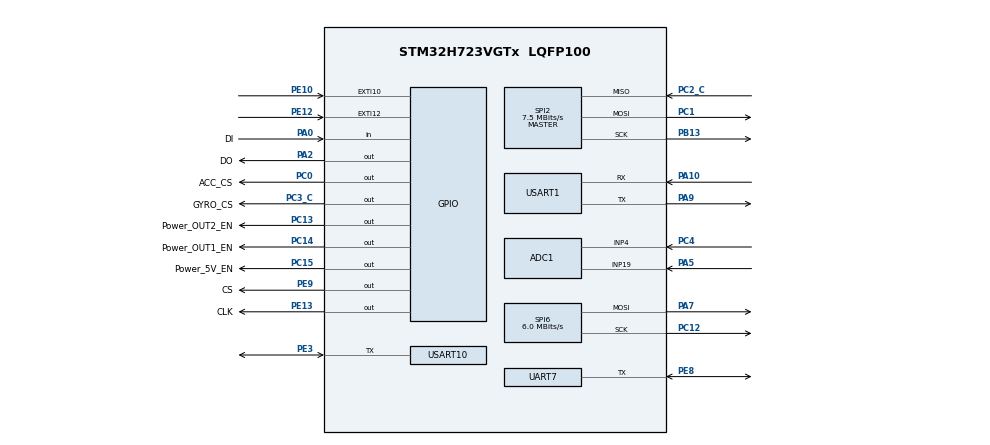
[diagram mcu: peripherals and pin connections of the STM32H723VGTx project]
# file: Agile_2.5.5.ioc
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ADC1.Channel-0\#ChannelRegularConversion=ADC_CHANNEL_4
ADC1.Channel-1\#ChannelRegularConversion=ADC_CHANNEL_19
ADC1.ClockPrescaler=ADC_CLOCK_ASYNC_DIV64
ADC1.ContinuousConvMode=ENABLE
ADC1.ConversionDataManagement=ADC_CONVERSIONDATA_DMA_CIRCULAR
ADC1.NbrOfConversion=2
ADC1.NbrOfConversionFlag=1
ADC1.OffsetNumber-0\#ChannelRegularConversion=ADC_OFFSET_NONE
ADC1.OffsetNumber-1\#ChannelRegularConversion=ADC_OFFSET_NONE
ADC1.OffsetSignedSaturation-0\#ChannelRegularConversion=DISABLE
ADC1.OffsetSignedSaturation-1\#ChannelRegularConversion=DISABLE
ADC1.Rank-0\#ChannelRegularConversion=1
ADC1.Rank-1\#ChannelRegularConversion=2
ADC1.SamplingTime-0\#ChannelRegularConversion=ADC_SAMPLETIME_32CYCLES_5
ADC1.SamplingTime-1\#ChannelRegularConversion=ADC_SAMPLETIME_32CYCLES_5
ADC1.master=1
Bdma.Request0=SPI6_TX
Bdma.RequestsNb=1
Bdma.SPI6_TX.0.Direction=DMA_MEMORY_TO_PERIPH
Bdma.SPI6_TX.0.EventEnable=DISABLE
Bdma.SPI6_TX.0.Instance=BDMA_Channel0
Bdma.SPI6_TX.0.MemDataAlignment=DMA_MDATAALIGN_BYTE
Bdma.SPI6_TX.0.MemInc=DMA_MINC_ENABLE
Bdma.SPI6_TX.0.Mode=DMA_NORMAL
Bdma.SPI6_TX.0.PeriphDataAlignment=DMA_PDATAALIGN_BYTE
Bdma.SPI6_TX.0.PeriphInc=DMA_PINC_DISABLE
Bdma.SPI6_TX.0.Polarity=HAL_DMAMUX_REQ_GEN_RISING
Bdma.SPI6_TX.0.Priority=DMA_PRIORITY_LOW
Bdma.SPI6_TX.0.RequestNumber=1
Bdma.SPI6_TX.0.SignalID=NONE
Bdma.SPI6_TX.0.SyncEnable=DISABLE
Bdma.SPI6_TX.0.SyncPolarity=HAL_DMAMUX_SYNC_NO_EVENT
Bdma.SPI6_TX.0.SyncRequestNumber=1
Bdma.SPI6_TX.0.SyncSignalID=NONE
CORTEX_M7.CPU_ICache=Enabled
CORTEX_M7.MPU_Control=__NULL
CORTEX_M7.default_mode_Activation=1
Dma.ADC1.0.Direction=DMA_PERIPH_TO_MEMORY
Dma.ADC1.0.EventEnable=DISABLE
Dma.ADC1.0.FIFOMode=DMA_FIFOMODE_DISABLE
Dma.ADC1.0.Instance=DMA1_Stream0
Dma.ADC1.0.MemDataAlignment=DMA_MDATAALIGN_HALFWORD
Dma.ADC1.0.MemInc=DMA_MINC_ENABLE
Dma.ADC1.0.Mode=DMA_CIRCULAR
Dma.ADC1.0.PeriphDataAlignment=DMA_PDATAALIGN_HALFWORD
Dma.ADC1.0.PeriphInc=DMA_PINC_DISABLE
Dma.ADC1.0.Polarity=HAL_DMAMUX_REQ_GEN_RISING
Dma.ADC1.0.Priority=DMA_PRIORITY_LOW
Dma.ADC1.0.RequestNumber=1
Dma.ADC1.0.SignalID=NONE
Dma.ADC1.0.SyncEnable=DISABLE
Dma.ADC1.0.SyncPolarity=HAL_DMAMUX_SYNC_NO_EVENT
Dma.ADC1.0.SyncRequestNumber=1
Dma.ADC1.0.SyncSignalID=NONE
Dma.Request0=ADC1
Dma.Request1=USART1_RX
Dma.Request2=USART1_TX
Dma.Request3=UART7_RX
Dma.Request4=UART7_TX
Dma.Request5=USART10_RX
Dma.Request6=USART10_TX
Dma.Request7=SPI2_TX
Dma.Request8=SPI2_RX
Dma.SPI2_RX.8.Direction=DMA_PERIPH_TO_MEMORY
Dma.SPI2_RX.8.EventEnable=DISABLE
Dma.SPI2_RX.8.FIFOMode=DMA_FIFOMODE_DISABLE
Dma.SPI2_RX.8.Instance=DMA2_Stream0
Dma.SPI2_RX.8.MemDataAlignment=DMA_MDATAALIGN_BYTE
Dma.SPI2_RX.8.MemInc=DMA_MINC_ENABLE
Dma.SPI2_RX.8.Mode=DMA_NORMAL
Dma.SPI2_RX.8.PeriphDataAlignment=DMA_PDATAALIGN_BYTE
Dma.SPI2_RX.8.PeriphInc=DMA_PINC_DISABLE
Dma.SPI2_RX.8.Polarity=HAL_DMAMUX_REQ_GEN_RISING
Dma.SPI2_RX.8.Priority=DMA_PRIORITY_LOW
Dma.SPI2_RX.8.RequestNumber=1
Dma.SPI2_RX.8.SignalID=NONE
Dma.SPI2_RX.8.SyncEnable=DISABLE
Dma.SPI2_RX.8.SyncPolarity=HAL_DMAMUX_SYNC_NO_EVENT
Dma.SPI2_RX.8.SyncRequestNumber=1
Dma.SPI2_RX.8.SyncSignalID=NONE
Dma.SPI2_TX.7.Direction=DMA_MEMORY_TO_PERIPH
Dma.SPI2_TX.7.EventEnable=DISABLE
Dma.SPI2_TX.7.FIFOMode=DMA_FIFOMODE_DISABLE
Dma.SPI2_TX.7.Instance=DMA1_Stream7
Dma.SPI2_TX.7.MemDataAlignment=DMA_MDATAALIGN_BYTE
Dma.SPI2_TX.7.MemInc=DMA_MINC_ENABLE
Dma.SPI2_TX.7.Mode=DMA_NORMAL
Dma.SPI2_TX.7.PeriphDataAlignment=DMA_PDATAALIGN_BYTE
Dma.SPI2_TX.7.PeriphInc=DMA_PINC_DISABLE
Dma.SPI2_TX.7.Polarity=HAL_DMAMUX_REQ_GEN_RISING
Dma.SPI2_TX.7.Priority=DMA_PRIORITY_LOW
Dma.SPI2_TX.7.RequestNumber=1
Dma.SPI2_TX.7.SignalID=NONE
Dma.SPI2_TX.7.SyncEnable=DISABLE
Dma.SPI2_TX.7.SyncPolarity=HAL_DMAMUX_SYNC_NO_EVENT
Dma.SPI2_TX.7.SyncRequestNumber=1
Dma.SPI2_TX.7.SyncSignalID=NONE
Dma.UART7_RX.3.Direction=DMA_PERIPH_TO_MEMORY
Dma.UART7_RX.3.EventEnable=DISABLE
Dma.UART7_RX.3.FIFOMode=DMA_FIFOMODE_DISABLE
Dma.UART7_RX.3.Instance=DMA1_Stream3
Dma.UART7_RX.3.MemDataAlignment=DMA_MDATAALIGN_BYTE
Dma.UART7_RX.3.MemInc=DMA_MINC_ENABLE
Dma.UART7_RX.3.Mode=DMA_NORMAL
Dma.UART7_RX.3.PeriphDataAlignment=DMA_PDATAALIGN_BYTE
Dma.UART7_RX.3.PeriphInc=DMA_PINC_DISABLE
Dma.UART7_RX.3.Polarity=HAL_DMAMUX_REQ_GEN_RISING
Dma.UART7_RX.3.Priority=DMA_PRIORITY_LOW
Dma.UART7_RX.3.RequestNumber=1
Dma.UART7_RX.3.SignalID=NONE
Dma.UART7_RX.3.SyncEnable=DISABLE
Dma.UART7_RX.3.SyncPolarity=HAL_DMAMUX_SYNC_NO_EVENT
Dma.UART7_RX.3.SyncRequestNumber=1
Dma.UART7_RX.3.SyncSignalID=NONE
Dma.UART7_TX.4.Direction=DMA_MEMORY_TO_PERIPH
Dma.UART7_TX.4.EventEnable=DISABLE
Dma.UART7_TX.4.FIFOMode=DMA_FIFOMODE_DISABLE
Dma.UART7_TX.4.Instance=DMA1_Stream4
Dma.UART7_TX.4.MemDataAlignment=DMA_MDATAALIGN_BYTE
Dma.UART7_TX.4.MemInc=DMA_MINC_ENABLE
Dma.UART7_TX.4.Mode=DMA_NORMAL
Dma.UART7_TX.4.PeriphDataAlignment=DMA_PDATAALIGN_BYTE
Dma.UART7_TX.4.PeriphInc=DMA_PINC_DISABLE
Dma.UART7_TX.4.Polarity=HAL_DMAMUX_REQ_GEN_RISING
Dma.UART7_TX.4.Priority=DMA_PRIORITY_LOW
Dma.UART7_TX.4.RequestNumber=1
Dma.UART7_TX.4.SignalID=NONE
Dma.UART7_TX.4.SyncEnable=DISABLE
Dma.UART7_TX.4.SyncPolarity=HAL_DMAMUX_SYNC_NO_EVENT
Dma.UART7_TX.4.SyncRequestNumber=1
Dma.UART7_TX.4.SyncSignalID=NONE
Dma.USART10_RX.5.Direction=DMA_PERIPH_TO_MEMORY
Dma.USART10_RX.5.EventEnable=DISABLE
Dma.USART10_RX.5.FIFOMode=DMA_FIFOMODE_DISABLE
Dma.USART10_RX.5.Instance=DMA1_Stream5
Dma.USART10_RX.5.MemDataAlignment=DMA_MDATAALIGN_BYTE
Dma.USART10_RX.5.MemInc=DMA_MINC_ENABLE
Dma.USART10_RX.5.Mode=DMA_NORMAL
Dma.USART10_RX.5.PeriphDataAlignment=DMA_PDATAALIGN_BYTE
Dma.USART10_RX.5.PeriphInc=DMA_PINC_DISABLE
Dma.USART10_RX.5.Polarity=HAL_DMAMUX_REQ_GEN_RISING
Dma.USART10_RX.5.Priority=DMA_PRIORITY_LOW
Dma.USART10_RX.5.RequestNumber=1
Dma.USART10_RX.5.SignalID=NONE
Dma.USART10_RX.5.SyncEnable=DISABLE
Dma.USART10_RX.5.SyncPolarity=HAL_DMAMUX_SYNC_NO_EVENT
Dma.USART10_RX.5.SyncRequestNumber=1
Dma.USART10_RX.5.SyncSignalID=NONE
Dma.USART10_TX.6.Direction=DMA_MEMORY_TO_PERIPH
Dma.USART10_TX.6.EventEnable=DISABLE
Dma.USART10_TX.6.FIFOMode=DMA_FIFOMODE_DISABLE
Dma.USART10_TX.6.Instance=DMA1_Stream6
Dma.USART10_TX.6.MemDataAlignment=DMA_MDATAALIGN_BYTE
Dma.USART10_TX.6.MemInc=DMA_MINC_ENABLE
Dma.USART10_TX.6.Mode=DMA_NORMAL
Dma.USART10_TX.6.PeriphDataAlignment=DMA_PDATAALIGN_BYTE
Dma.USART10_TX.6.PeriphInc=DMA_PINC_DISABLE
Dma.USART10_TX.6.Polarity=HAL_DMAMUX_REQ_GEN_RISING
Dma.USART10_TX.6.Priority=DMA_PRIORITY_LOW
Dma.USART10_TX.6.RequestNumber=1
Dma.USART10_TX.6.SignalID=NONE
Dma.USART10_TX.6.SyncEnable=DISABLE
Dma.USART10_TX.6.SyncPolarity=HAL_DMAMUX_SYNC_NO_EVENT
Dma.USART10_TX.6.SyncRequestNumber=1
Dma.USART10_TX.6.SyncSignalID=NONE
Dma.USART1_RX.1.Direction=DMA_PERIPH_TO_MEMORY
Dma.USART1_RX.1.EventEnable=DISABLE
Dma.USART1_RX.1.FIFOMode=DMA_FIFOMODE_DISABLE
Dma.USART1_RX.1.Instance=DMA1_Stream1
Dma.USART1_RX.1.MemDataAlignment=DMA_MDATAALIGN_BYTE
Dma.USART1_RX.1.MemInc=DMA_MINC_ENABLE
Dma.USART1_RX.1.Mode=DMA_NORMAL
Dma.USART1_RX.1.PeriphDataAlignment=DMA_PDATAALIGN_BYTE
Dma.USART1_RX.1.PeriphInc=DMA_PINC_DISABLE
Dma.USART1_RX.1.Polarity=HAL_DMAMUX_REQ_GEN_RISING
Dma.USART1_RX.1.Priority=DMA_PRIORITY_LOW
Dma.USART1_RX.1.RequestNumber=1
Dma.USART1_RX.1.SignalID=NONE
Dma.USART1_RX.1.SyncEnable=DISABLE
Dma.USART1_RX.1.SyncPolarity=HAL_DMAMUX_SYNC_NO_EVENT
Dma.USART1_RX.1.SyncRequestNumber=1
Dma.USART1_RX.1.SyncSignalID=NONE
Dma.USART1_TX.2.Direction=DMA_MEMORY_TO_PERIPH
Dma.USART1_TX.2.EventEnable=DISABLE
Dma.USART1_TX.2.FIFOMode=DMA_FIFOMODE_DISABLE
Dma.USART1_TX.2.Instance=DMA1_Stream2
Dma.USART1_TX.2.MemDataAlignment=DMA_MDATAALIGN_BYTE
Dma.USART1_TX.2.MemInc=DMA_MINC_ENABLE
Dma.USART1_TX.2.Mode=DMA_NORMAL
Dma.USART1_TX.2.PeriphDataAlignment=DMA_PDATAALIGN_BYTE
Dma.USART1_TX.2.PeriphInc=DMA_PINC_DISABLE
Dma.USART1_TX.2.Polarity=HAL_DMAMUX_REQ_GEN_RISING
Dma.USART1_TX.2.Priority=DMA_PRIORITY_LOW
Dma.USART1_TX.2.RequestNumber=1
Dma.USART1_TX.2.SignalID=NONE
Dma.USART1_TX.2.SyncEnable=DISABLE
Dma.USART1_TX.2.SyncPolarity=HAL_DMAMUX_SYNC_NO_EVENT
Dma.USART1_TX.2.SyncRequestNumber=1
Dma.USART1_TX.2.SyncSignalID=NONE
FREERTOS.MEMORY_ALLOCATION=1
FREERTOS.Queues01=cliEvtQ,64,void *,0,Static,cliEvtQBuffer,cliEvtQControlBlock
FREERTOS.Tasks01=defaultTask,0,512,StartDefaultTask,Default,NULL,Static,defaultTaskBuffer,defaultTaskControlBlock;INS_TASK,3,1024,INS_Task_Entry,Default,NULL,Static,INS_TASKBuffer,INS_TASKControlBlock;BALANCE_TASK,1,1024,Balance_Task_Entry,Default,NULL,Static,BALANCE_TASKBuffer,BALANCE_TASKControlBlock;UART1_LOG_TASK,-2,768,UART1_Log_Task_Entry,Default,NULL,Static,UART1_LOG_TASKBuffer,UART1_LOG_TASKBlock
FREERTOS.configENABLE_FPU=1
FREERTOS.configUSE_NEWLIB_REENTRANT=1
FREERTOS.copyHeapFile=0
Mcu.Family=STM32H7
Mcu.Name=STM32H723VGTx
Mcu.Package=LQFP100
NVIC.BDMA_Channel0_IRQn=true\:5\:0\:false\:false\:true\:true\:false\:true\:true
NVIC.DMA1_Stream0_IRQn=true\:5\:0\:false\:false\:true\:true\:false\:true\:true
NVIC.DMA1_Stream1_IRQn=true\:5\:0\:false\:false\:true\:true\:false\:true\:true
NVIC.DMA1_Stream2_IRQn=true\:5\:0\:false\:false\:true\:true\:false\:true\:true
NVIC.DMA1_Stream3_IRQn=true\:5\:0\:false\:false\:true\:true\:false\:true\:true
NVIC.DMA1_Stream4_IRQn=true\:5\:0\:false\:false\:true\:true\:false\:true\:true
NVIC.DMA1_Stream5_IRQn=true\:5\:0\:false\:false\:true\:true\:false\:true\:true
NVIC.DMA1_Stream6_IRQn=true\:5\:0\:false\:false\:true\:true\:false\:true\:true
NVIC.DMA1_Stream7_IRQn=true\:5\:0\:false\:false\:true\:true\:false\:true\:true
NVIC.DMA2_Stream0_IRQn=true\:5\:0\:false\:false\:true\:true\:false\:true\:true
NVIC.PriorityGroup=NVIC_PRIORITYGROUP_4
NVIC.SPI2_IRQn=true\:5\:0\:false\:false\:true\:true\:false\:true\:true
NVIC.SPI6_IRQn=true\:5\:0\:false\:false\:true\:true\:false\:true\:true
NVIC.TIM6_DAC_IRQn=true\:15\:0\:false\:false\:true\:false\:false\:true\:true
NVIC.TimeBase=TIM6_DAC_IRQn
NVIC.TimeBaseIP=TIM6
NVIC.UART7_IRQn=true\:5\:0\:false\:false\:true\:true\:true\:true\:true
NVIC.USART10_IRQn=true\:5\:0\:false\:false\:true\:true\:true\:true\:true
NVIC.USART1_IRQn=true\:5\:0\:false\:false\:true\:true\:true\:true\:true
PA0.GPIO_Label=DI
PA0.Signal=GPIO_Input
PA10.Mode=Asynchronous
PA10.Signal=USART1_RX
PA13(JTMS/SWDIO).Mode=Serial_Wire
PA13(JTMS/SWDIO).Signal=DEBUG_JTMS-SWDIO
PA14(JTCK/SWCLK).Mode=Serial_Wire
PA14(JTCK/SWCLK).Signal=DEBUG_JTCK-SWCLK
PA2.GPIO_Label=DO
PA2.Signal=GPIO_Output
PA5.Signal=ADCx_INP19
PA7.Mode=TX_Only_Simplex_Unidirect_Master
PA7.Signal=SPI6_MOSI
PA9.Mode=Asynchronous
PA9.Signal=USART1_TX
PB13.Mode=Full_Duplex_Master
PB13.Signal=SPI2_SCK
PC0.GPIO_Label=ACC_CS
PC0.Signal=GPIO_Output
PC1.Mode=Full_Duplex_Master
PC1.Signal=SPI2_MOSI
PC12.Mode=TX_Only_Simplex_Unidirect_Master
PC12.Signal=SPI6_SCK
PC13.GPIO_Label=Power_OUT2_EN
PC13.Signal=GPIO_Output
PC14-OSC32_IN.GPIO_Label=Power_OUT1_EN
PC14-OSC32_IN.Signal=GPIO_Output
PC15-OSC32_OUT.GPIO_Label=Power_5V_EN
PC15-OSC32_OUT.Signal=GPIO_Output
PC2_C.Mode=Full_Duplex_Master
PC2_C.Signal=SPI2_MISO
PC3_C.GPIO_Label=GYRO_CS
PC3_C.Signal=GPIO_Output
PC4.Signal=ADCx_INP4
PE10.Signal=GPXTI10
PE12.Signal=GPXTI12
PE13.GPIO_Label=CLK
PE13.Signal=GPIO_Output
PE3.GPIO_ModeDefaultOD=GPIO_MODE_AF_PP
PE3.Mode=Half_duplex(single_wire_mode)
PE3.Signal=USART10_TX
PE8.GPIO_ModeDefaultOD=GPIO_MODE_AF_PP
PE8.Mode=Half_duplex(single_wire_mode)
PE8.Signal=UART7_TX
PE9.GPIO_Label=CS
PE9.Signal=GPIO_Output
PH0-OSC_IN.Mode=HSE-External-Oscillator
PH0-OSC_IN.Signal=RCC_OSC_IN
PH1-OSC_OUT.Mode=HSE-External-Oscillator
PH1-OSC_OUT.Signal=RCC_OSC_OUT
ProjectManager.HeapSize=0x200
ProjectManager.StackSize=0x400
ProjectManager.TargetToolchain=STM32CubeIDE
RCC.ADCCLockSelection=RCC_ADCCLKSOURCE_PLL3
RCC.ADCFreq_Value=96000000
RCC.APB1Freq_Value=137500000
RCC.APB2Freq_Value=137500000
RCC.APB3Freq_Value=137500000
RCC.APB4Freq_Value=137500000
RCC.CortexFreq_Value=550000000
RCC.D1PPRE=RCC_APB3_DIV2
RCC.D2PPRE1=RCC_APB1_DIV2
RCC.D2PPRE2=RCC_APB2_DIV2
RCC.D3PPRE=RCC_APB4_DIV2
RCC.DIVM1=3
RCC.DIVM2=2
RCC.DIVM3=3
RCC.DIVN1=68
RCC.DIVN2=20
RCC.DIVN3=48
RCC.DIVP1=1
RCC.DIVP2=1
RCC.DIVP3=1
RCC.DIVR3=4
RCC.HCLKFreq_Value=275000000
RCC.HPRE=RCC_HCLK_DIV2
RCC.HSE_VALUE=24000000
RCC.PLL2FRACN=0
RCC.PLL3FRACN=0
RCC.PLLFRACN=6144
RCC.PLLSourceVirtual=RCC_PLLSOURCE_HSE
RCC.SPI123CLockSelection=RCC_SPI123CLKSOURCE_PLL2
RCC.SPI6CLockSelection=RCC_SPI6CLKSOURCE_HSE
RCC.SYSCLKFreq_VALUE=550000000
RCC.SYSCLKSource=RCC_SYSCLKSOURCE_PLLCLK
RCC.USBFreq_Value=275000000
SH.ADCx_INP19.0=ADC1_INP19,IN19-Single-Ended
SH.ADCx_INP4.0=ADC1_INP4,IN4-Single-Ended
SPI2.BaudRatePrescaler=SPI_BAUDRATEPRESCALER_32
SPI2.CLKPhase=SPI_PHASE_2EDGE
SPI2.CLKPolarity=SPI_POLARITY_HIGH
SPI2.CalculateBaudRate=7.5 MBits/s
SPI2.DataSize=SPI_DATASIZE_8BIT
SPI2.Direction=SPI_DIRECTION_2LINES
SPI2.Mode=SPI_MODE_MASTER
SPI2.VirtualType=VM_MASTER
SPI6.BaudRatePrescaler=SPI_BAUDRATEPRESCALER_4
SPI6.CLKPhase=SPI_PHASE_2EDGE
SPI6.CalculateBaudRate=6.0 MBits/s
SPI6.DataSize=SPI_DATASIZE_8BIT
SPI6.Direction=SPI_DIRECTION_2LINES_TXONLY
SPI6.Mode=SPI_MODE_MASTER
SPI6.VirtualType=VM_MASTER
UART7.BaudRate=38400
UART7.RxPinLevelInvertParam=UART_ADVFEATURE_RXINV_ENABLE
UART7.TxPinLevelInvertParam=UART_ADVFEATURE_TXINV_ENABLE
USART1.VirtualMode-Asynchronous=VM_ASYNC
USART10.BaudRate=38400
USART10.RxPinLevelInvertParam=ADVFEATURE_RXINV_ENABLE
USART10.TxPinLevelInvertParam=ADVFEATURE_TXINV_ENABLE
USART10.VirtualMode=VM_ASYNC
VP_FREERTOS_VS_CMSIS_V1.Mode=CMSIS_V1
VP_MEMORYMAP_VS_MEMORYMAP.Mode=CurAppReg
VP_SYS_VS_tim6.Mode=TIM6
board=custom

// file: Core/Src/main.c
/* USER CODE BEGIN Header */
/**
  ******************************************************************************
  * @file           : main.c
  * @brief          : Main program body
  ******************************************************************************
  * @attention
  *
  * Copyright (c) 2026 STMicroelectronics.
  * All rights reserved.
  *
  * This software is licensed under terms that can be found in the LICENSE file
  * in the root directory of this software component.
  * If no LICENSE file comes with this software, it is provided AS-IS.
  *
  ******************************************************************************
  */
/* USER CODE END Header */
#include "main.h"
#include "cmsis_os.h"
#include "adc.h"
#include "bdma.h"
#include "dma.h"
#include "spi.h"
#include "usart.h"
#include "gpio.h"

/* USER CODE BEGIN Includes */
#include "bsp_dwt.h"
#include "BMI088driver.h"
#include "uart1_log.h"
#include "vofa_uart1.h"

/* USER CODE END Includes */

void SystemClock_Config(void);
void MX_FREERTOS_Init(void);

int main(void)
{

  /* Enable the CPU Cache */

  /* Enable I-Cache---------------------------------------------------------*/
  SCB_EnableICache();

  /* MCU Configuration--------------------------------------------------------*/

  /* Reset of all peripherals, Initializes the Flash interface and the Systick. */
  HAL_Init();

  /* Configure the system clock */
  SystemClock_Config();

  /* Initialize all configured peripherals */
  MX_GPIO_Init();
  MX_BDMA_Init();
  MX_DMA_Init();
  MX_SPI6_Init();
  MX_USART1_UART_Init();
  MX_ADC1_Init();
  MX_UART7_Init();
  MX_USART10_UART_Init();
  MX_SPI2_Init();
  /* USER CODE BEGIN 2 */
  DWT_Init(550);

  while (BMI088_init(&hspi2, 0) != BMI088_NO_ERROR)
  {
    HAL_Delay(10);
  }
  UART1_LogInit();
  VOFA_UART1_Init();

  /* USER CODE END 2 */

  /* Call init function for freertos objects (in cmsis_os2.c) */
  MX_FREERTOS_Init();

  /* Start scheduler */
  osKernelStart();

  /* We should never get here as control is now taken by the scheduler */

  /* Infinite loop */
  while (1)
  {

  }
}

void SystemClock_Config(void)
{
  RCC_OscInitTypeDef RCC_OscInitStruct = {0};
  RCC_ClkInitTypeDef RCC_ClkInitStruct = {0};

  /** Supply configuration update enable
  */
  HAL_PWREx_ConfigSupply(PWR_LDO_SUPPLY);

  /** Configure the main internal regulator output voltage
  */
  __HAL_PWR_VOLTAGESCALING_CONFIG(PWR_REGULATOR_VOLTAGE_SCALE0);

  while(!__HAL_PWR_GET_FLAG(PWR_FLAG_VOSRDY)) {}

  /** Initializes the RCC Oscillators according to the specified parameters
  * in the RCC_OscInitTypeDef structure.
  */
  RCC_OscInitStruct.OscillatorType = RCC_OSCILLATORTYPE_HSE;
  RCC_OscInitStruct.HSEState = RCC_HSE_ON;
  RCC_OscInitStruct.PLL.PLLState = RCC_PLL_ON;
  RCC_OscInitStruct.PLL.PLLSource = RCC_PLLSOURCE_HSE;
  RCC_OscInitStruct.PLL.PLLM = 3;
  RCC_OscInitStruct.PLL.PLLN = 68;
  RCC_OscInitStruct.PLL.PLLP = 1;
  RCC_OscInitStruct.PLL.PLLQ = 2;
  RCC_OscInitStruct.PLL.PLLR = 2;
  RCC_OscInitStruct.PLL.PLLRGE = RCC_PLL1VCIRANGE_3;
  RCC_OscInitStruct.PLL.PLLVCOSEL = RCC_PLL1VCOWIDE;
  RCC_OscInitStruct.PLL.PLLFRACN = 6144;
  if (HAL_RCC_OscConfig(&RCC_OscInitStruct) != HAL_OK)
  {
    Error_Handler();
  }

  /** Initializes the CPU, AHB and APB buses clocks
  */
  RCC_ClkInitStruct.ClockType = RCC_CLOCKTYPE_HCLK|RCC_CLOCKTYPE_SYSCLK
                              |RCC_CLOCKTYPE_PCLK1|RCC_CLOCKTYPE_PCLK2
                              |RCC_CLOCKTYPE_D3PCLK1|RCC_CLOCKTYPE_D1PCLK1;
  RCC_ClkInitStruct.SYSCLKSource = RCC_SYSCLKSOURCE_PLLCLK;
  RCC_ClkInitStruct.SYSCLKDivider = RCC_SYSCLK_DIV1;
  RCC_ClkInitStruct.AHBCLKDivider = RCC_HCLK_DIV2;
  RCC_ClkInitStruct.APB3CLKDivider = RCC_APB3_DIV2;
  RCC_ClkInitStruct.APB1CLKDivider = RCC_APB1_DIV2;
  RCC_ClkInitStruct.APB2CLKDivider = RCC_APB2_DIV2;
  RCC_ClkInitStruct.APB4CLKDivider = RCC_APB4_DIV2;

  if (HAL_RCC_ClockConfig(&RCC_ClkInitStruct, FLASH_LATENCY_3) != HAL_OK)
  {
    Error_Handler();
  }
}

void HAL_TIM_PeriodElapsedCallback(TIM_HandleTypeDef *htim)
{
  if (htim->Instance == TIM6)
  {
    HAL_IncTick();
  }
}

void Error_Handler(void)
{
  __disable_irq();
  while (1)
  {
  }
}
